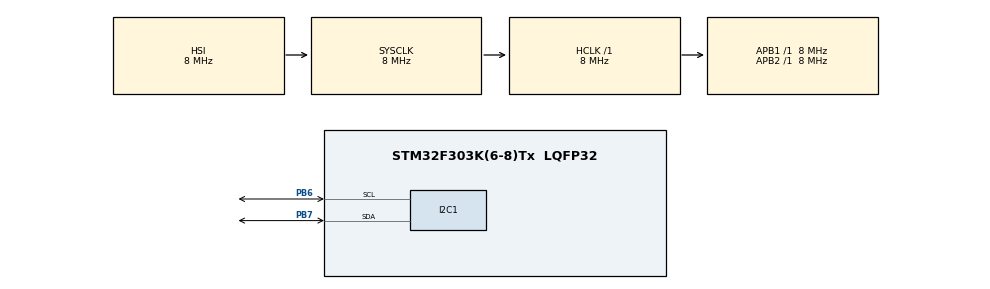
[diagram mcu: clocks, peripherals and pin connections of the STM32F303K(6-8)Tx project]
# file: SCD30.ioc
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I2C1.Timing=0x00201D2B
Mcu.Family=STM32F3
Mcu.Name=STM32F303K(6-8)Tx
Mcu.Package=LQFP32
NVIC.PriorityGroup=NVIC_PRIORITYGROUP_4
PA13.Mode=Trace_Asynchronous_SW
PA13.Signal=SYS_JTMS-SWDIO
PA14.Mode=Trace_Asynchronous_SW
PA14.Signal=SYS_JTCK-SWCLK
PB3.Mode=Trace_Asynchronous_SW
PB3.Signal=SYS_JTDO-TRACESWO
PB6.GPIO_Pu=GPIO_PULLUP
PB6.Mode=I2C
PB6.Signal=I2C1_SCL
PB7.GPIO_Pu=GPIO_PULLUP
PB7.Mode=I2C
PB7.Signal=I2C1_SDA
ProjectManager.HeapSize=0x200
ProjectManager.StackSize=0x400
ProjectManager.TargetToolchain=STM32CubeIDE
RCC.AHBFreq_Value=8000000
RCC.APB1Freq_Value=8000000
RCC.APB2Freq_Value=8000000
RCC.CortexFreq_Value=8000000
RCC.HSE_VALUE=8000000
RCC.HSI_VALUE=8000000
RCC.SYSCLKFreq_VALUE=8000000
board=custom

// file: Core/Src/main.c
/* USER CODE BEGIN Header */
/**
 ******************************************************************************
 * @file           : main.c
 * @brief          : Main program body
 ******************************************************************************
 * @attention
 *
 * Copyright (c) 2025 STMicroelectronics.
 * All rights reserved.
 *
 * This software is licensed under terms that can be found in the LICENSE file
 * in the root directory of this software component.
 * If no LICENSE file comes with this software, it is provided AS-IS.
 *
 ******************************************************************************
 */
/* USER CODE END Header */
#include "main.h"

/* USER CODE BEGIN Includes */
#include <stdio.h>
#include "scd30.h"

// For semihosting printf support
extern void initialise_monitor_handles(void);
/* USER CODE END Includes */

I2C_HandleTypeDef hi2c1;

void SystemClock_Config(void);
static void MX_GPIO_Init(void);
static void MX_I2C1_Init(void);
/* USER CODE BEGIN PFP */

void I2C_Scan(I2C_HandleTypeDef *hi2c);

/* USER CODE END PFP */

/* USER CODE BEGIN 0 */

void I2C_Scan(I2C_HandleTypeDef *hi2c)
{
  printf("Scanning I2C bus...\r\n");
  for (uint8_t addr = 1; addr < 127; addr++)
  {
    if (HAL_I2C_IsDeviceReady(hi2c, addr << 1, 1, 10) == HAL_OK)
    {
      printf("Device found at 0x%02X\r\n", addr);
    }
  }
}

/* USER CODE END 0 */

int main(void)
{

  /* MCU Configuration--------------------------------------------------------*/

  /* Reset of all peripherals, Initializes the Flash interface and the Systick. */
  HAL_Init();

  /* Configure the system clock */
  SystemClock_Config();

  /* Initialize all configured peripherals */
  MX_GPIO_Init();
  MX_I2C1_Init();
  /* USER CODE BEGIN 2 */
  initialise_monitor_handles();

  // Scan I2C bus for devices
  I2C_Scan(&hi2c1);

  // Start SCD30 measurement
  if (SCD30_StartMeasurement(&hi2c1) == HAL_OK)
  {
    // Measurement started successfully
  }
  else
  {
    // Error starting measurement
  }

  float co2 = 0, temperature = 0, humidity = 0;

  uint8_t data_ready = 0;

  /* USER CODE END 2 */

  /* Infinite loop */
  while (1)
  {

    /* USER CODE BEGIN 3 */

    // Poll data ready status
    if (SCD30_DataReady(&hi2c1, &data_ready) == HAL_OK && data_ready)
    {
      if (SCD30_ReadMeasurement(&hi2c1, &co2, &temperature, &humidity) == HAL_OK)
      {
        printf("CO2: %.2f ppm, Temp: %.2f C, Humidity: %.2f %%\r\n", co2, temperature, humidity);
      }
      else
      {
        printf("Error reading measurement\r\n");
      }
    }
    else
    {
      printf("Waiting for data...\r\n");
    }
    HAL_Delay(2000);
  }
  /* USER CODE END 3 */
}

void SystemClock_Config(void)
{
  RCC_OscInitTypeDef RCC_OscInitStruct = {0};
  RCC_ClkInitTypeDef RCC_ClkInitStruct = {0};
  RCC_PeriphCLKInitTypeDef PeriphClkInit = {0};

  /** Initializes the RCC Oscillators according to the specified parameters
   * in the RCC_OscInitTypeDef structure.
   */
  RCC_OscInitStruct.OscillatorType = RCC_OSCILLATORTYPE_HSI;
  RCC_OscInitStruct.HSIState = RCC_HSI_ON;
  RCC_OscInitStruct.HSICalibrationValue = RCC_HSICALIBRATION_DEFAULT;
  RCC_OscInitStruct.PLL.PLLState = RCC_PLL_NONE;
  if (HAL_RCC_OscConfig(&RCC_OscInitStruct) != HAL_OK)
  {
    Error_Handler();
  }

  /** Initializes the CPU, AHB and APB buses clocks
   */
  RCC_ClkInitStruct.ClockType = RCC_CLOCKTYPE_HCLK | RCC_CLOCKTYPE_SYSCLK | RCC_CLOCKTYPE_PCLK1 | RCC_CLOCKTYPE_PCLK2;
  RCC_ClkInitStruct.SYSCLKSource = RCC_SYSCLKSOURCE_HSI;
  RCC_ClkInitStruct.AHBCLKDivider = RCC_SYSCLK_DIV1;
  RCC_ClkInitStruct.APB1CLKDivider = RCC_HCLK_DIV1;
  RCC_ClkInitStruct.APB2CLKDivider = RCC_HCLK_DIV1;

  if (HAL_RCC_ClockConfig(&RCC_ClkInitStruct, FLASH_LATENCY_0) != HAL_OK)
  {
    Error_Handler();
  }
  PeriphClkInit.PeriphClockSelection = RCC_PERIPHCLK_I2C1;
  PeriphClkInit.I2c1ClockSelection = RCC_I2C1CLKSOURCE_HSI;
  if (HAL_RCCEx_PeriphCLKConfig(&PeriphClkInit) != HAL_OK)
  {
    Error_Handler();
  }
}

static void MX_I2C1_Init(void)
{

  hi2c1.Instance = I2C1;
  hi2c1.Init.Timing = 0x00201D2B;
  hi2c1.Init.OwnAddress1 = 0;
  hi2c1.Init.AddressingMode = I2C_ADDRESSINGMODE_7BIT;
  hi2c1.Init.DualAddressMode = I2C_DUALADDRESS_DISABLE;
  hi2c1.Init.OwnAddress2 = 0;
  hi2c1.Init.OwnAddress2Masks = I2C_OA2_NOMASK;
  hi2c1.Init.GeneralCallMode = I2C_GENERALCALL_DISABLE;
  hi2c1.Init.NoStretchMode = I2C_NOSTRETCH_DISABLE;
  if (HAL_I2C_Init(&hi2c1) != HAL_OK)
  {
    Error_Handler();
  }

  /** Configure Analogue filter
   */
  if (HAL_I2CEx_ConfigAnalogFilter(&hi2c1, I2C_ANALOGFILTER_ENABLE) != HAL_OK)
  {
    Error_Handler();
  }

  /** Configure Digital filter
   */
  if (HAL_I2CEx_ConfigDigitalFilter(&hi2c1, 0) != HAL_OK)
  {
    Error_Handler();
  }
}

static void MX_GPIO_Init(void)
{

  /* GPIO Ports Clock Enable */
  __HAL_RCC_GPIOA_CLK_ENABLE();
  __HAL_RCC_GPIOB_CLK_ENABLE();

}

void Error_Handler(void)
{
  __disable_irq();
  while (1)
  {
  }
}
